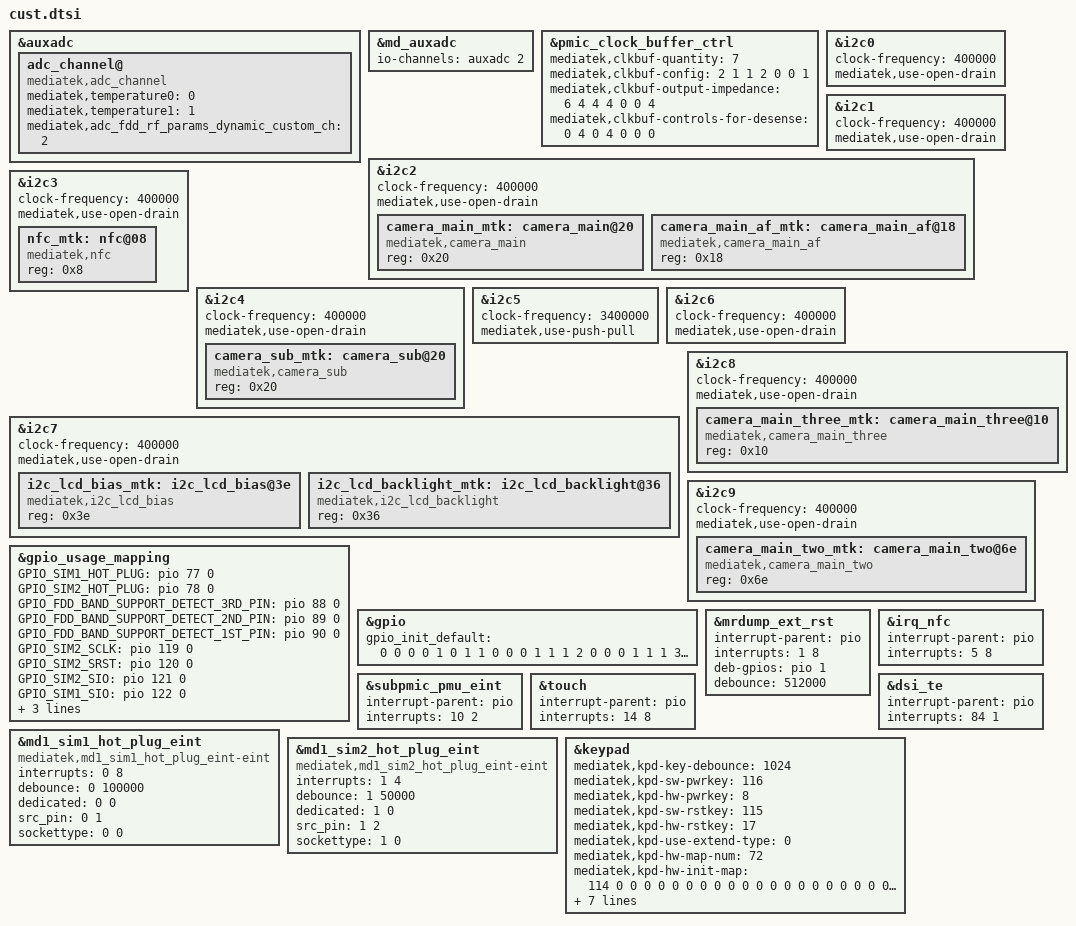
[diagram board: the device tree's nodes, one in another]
// SPDX-License-Identifier: GPL-2.0
/*
 * AQUOS wish4 (sx4) pin, EINT, I2C device, keypad and ADC configuration.
 *
 * MediaTek's DCT tool generates this file from the board's codegen.dws, which is
 * not part of the Sharp kernel release. Reconstructed from the stock dtbo; the
 * resulting dtbo.img matches the stock one byte for byte.
 */

&auxadc {
	adc_channel@ {
		compatible = "mediatek,adc_channel";
		mediatek,temperature0 = <0>;
		mediatek,temperature1 = <1>;
		mediatek,adc_fdd_rf_params_dynamic_custom_ch = <2>;
		status = "okay";
	};
};

&md_auxadc {
	io-channels = <&auxadc 2>;
};

&pmic_clock_buffer_ctrl {
	mediatek,clkbuf-quantity = <7>;
	mediatek,clkbuf-config = <2 1 1 2 0 0 1>;
	mediatek,clkbuf-output-impedance = <6 4 4 4 0 0 4>;
	mediatek,clkbuf-controls-for-desense = <0 4 0 4 0 0 0>;
	status = "okay";
};

&i2c0 {
	#address-cells = <1>;
	#size-cells = <0>;
	clock-frequency = <400000>;
	mediatek,use-open-drain;
};

&i2c1 {
	#address-cells = <1>;
	#size-cells = <0>;
	clock-frequency = <400000>;
	mediatek,use-open-drain;
};

&i2c2 {
	#address-cells = <1>;
	#size-cells = <0>;
	clock-frequency = <400000>;
	mediatek,use-open-drain;

	camera_main_mtk: camera_main@20 {
		compatible = "mediatek,camera_main";
		reg = <0x20>;
		status = "okay";
	};

	camera_main_af_mtk: camera_main_af@18 {
		compatible = "mediatek,camera_main_af";
		reg = <0x18>;
		status = "okay";
	};
};

&i2c3 {
	#address-cells = <1>;
	#size-cells = <0>;
	clock-frequency = <400000>;
	mediatek,use-open-drain;

	nfc_mtk: nfc@08 {
		compatible = "mediatek,nfc";
		reg = <0x8>;
		status = "okay";
	};
};

&i2c4 {
	#address-cells = <1>;
	#size-cells = <0>;
	clock-frequency = <400000>;
	mediatek,use-open-drain;

	camera_sub_mtk: camera_sub@20 {
		compatible = "mediatek,camera_sub";
		reg = <0x20>;
		status = "okay";
	};
};

&i2c5 {
	#address-cells = <1>;
	#size-cells = <0>;
	clock-frequency = <3400000>;
	mediatek,use-push-pull;
};

&i2c6 {
	#address-cells = <1>;
	#size-cells = <0>;
	clock-frequency = <400000>;
	mediatek,use-open-drain;
};

&i2c7 {
	#address-cells = <1>;
	#size-cells = <0>;
	clock-frequency = <400000>;
	mediatek,use-open-drain;

	i2c_lcd_bias_mtk: i2c_lcd_bias@3e {
		compatible = "mediatek,i2c_lcd_bias";
		reg = <0x3e>;
		status = "okay";
	};

	i2c_lcd_backlight_mtk: i2c_lcd_backlight@36 {
		compatible = "mediatek,i2c_lcd_backlight";
		reg = <0x36>;
		status = "okay";
	};
};

&i2c8 {
	#address-cells = <1>;
	#size-cells = <0>;
	clock-frequency = <400000>;
	mediatek,use-open-drain;

	camera_main_three_mtk: camera_main_three@10 {
		compatible = "mediatek,camera_main_three";
		reg = <0x10>;
		status = "okay";
	};
};

&i2c9 {
	#address-cells = <1>;
	#size-cells = <0>;
	clock-frequency = <400000>;
	mediatek,use-open-drain;

	camera_main_two_mtk: camera_main_two@6e {
		compatible = "mediatek,camera_main_two";
		reg = <0x6e>;
		status = "okay";
	};
};

&gpio_usage_mapping {
	GPIO_SIM1_HOT_PLUG = <&pio 77 0>;
	GPIO_SIM2_HOT_PLUG = <&pio 78 0>;
	GPIO_FDD_BAND_SUPPORT_DETECT_3RD_PIN = <&pio 88 0>;
	GPIO_FDD_BAND_SUPPORT_DETECT_2ND_PIN = <&pio 89 0>;
	GPIO_FDD_BAND_SUPPORT_DETECT_1ST_PIN = <&pio 90 0>;
	GPIO_SIM2_SCLK = <&pio 119 0>;
	GPIO_SIM2_SRST = <&pio 120 0>;
	GPIO_SIM2_SIO = <&pio 121 0>;
	GPIO_SIM1_SIO = <&pio 122 0>;
	GPIO_SIM1_SRST = <&pio 123 0>;
	GPIO_SIM1_SCLK = <&pio 124 0>;
	GPIO_RF_PWREN_RST_PIN = <&pio 170 0>;
};

&gpio {
	gpio_init_default = <0 0 0 0 1 0 1 1 0 0 0 1 1 1 2 0 0 0 1 1 1 3 0 0 0 1 0 1 4 0 0 0 1 1 1 5 0 0 0 1 0 1 6 0 1 0 1 0 1 7 0 1 0 1 0 1 8 7 0 0 1 0 1 9 0 0 0 1 1 1 10 0 0 0 1 1 1 11 0 1 0 1 0 1 12 2 0 0 0 0 0 13 2 0 0 0 0 0 14 0 0 0 1 0 1 15 0 1 0 1 0 1 16 7 0 0 1 0 1 17 7 0 0 1 0 1 18 7 0 0 1 0 1 19 7 0 0 0 0 1 20 7 0 0 1 0 1 21 0 1 0 1 0 1 22 0 0 0 1 0 1 23 7 0 0 1 0 1 24 7 0 0 1 0 1 25 7 0 0 1 0 1 26 7 0 0 1 0 1 27 1 0 0 0 0 1 28 1 0 0 0 0 1 29 1 0 0 0 0 1 30 1 0 0 1 0 1 31 2 0 0 0 0 1 32 2 0 0 0 0 1 33 2 0 0 0 0 1 34 2 0 0 1 0 1 35 0 1 0 0 0 0 36 0 1 0 0 0 0 37 0 1 0 0 0 0 38 0 1 0 1 0 0 39 0 0 0 1 1 1 40 1 0 0 0 0 1 41 1 0 0 0 0 1 42 1 0 0 1 0 1 43 1 0 0 0 0 1 44 0 1 0 1 0 1 45 0 1 0 1 0 1 46 0 0 0 1 0 0 47 0 1 0 1 0 1 48 0 0 0 1 0 1 49 1 0 0 1 0 1 50 1 0 0 1 0 1 51 1 0 0 1 0 1 52 1 0 0 0 0 1 53 0 1 0 1 0 1 54 0 1 0 1 0 1 55 0 1 0 1 0 1 56 0 1 0 1 0 1 57 0 1 1 1 0 0 58 0 1 0 1 0 1 59 1 0 0 1 0 1 60 0 1 0 1 0 1 61 1 0 0 1 1 1 62 1 0 0 0 0 1 63 1 0 0 1 1 1 64 1 0 0 0 0 1 77 1 0 0 0 0 0 78 1 0 0 1 1 1 79 1 0 0 1 1 1 80 1 0 0 1 1 1 81 3 0 0 1 0 1 82 0 1 0 1 0 1 83 1 0 0 0 0 1 84 1 0 0 1 0 1 85 1 0 0 0 0 1 86 1 0 0 0 0 1 87 2 0 0 1 0 1 88 0 0 0 0 0 0 89 0 0 0 0 0 0 90 0 0 0 0 0 0 91 0 0 0 0 0 1 92 0 1 0 1 0 1 93 0 1 0 1 0 1 94 0 1 0 1 0 1 95 1 0 0 1 0 1 96 1 0 0 1 0 1 97 2 0 0 0 0 0 98 2 0 0 0 0 0 99 2 0 0 1 1 1 100 2 0 0 1 1 1 101 1 0 0 1 1 1 102 1 0 0 1 1 1 103 1 0 0 1 1 1 104 1 0 0 1 1 1 105 1 0 0 1 1 1 106 1 0 0 1 1 1 107 1 0 0 1 1 1 108 1 0 0 1 1 1 109 1 0 0 1 1 1 110 1 0 0 1 1 1 111 1 0 0 1 1 1 112 1 0 0 1 1 1 113 1 0 0 1 1 1 114 1 0 0 1 1 1 115 1 0 0 1 0 1 116 1 0 0 1 0 1 117 0 0 0 1 0 1 118 0 0 0 1 0 1 119 1 0 0 0 0 1 120 1 0 0 0 0 1 121 1 0 0 1 1 1 122 1 0 0 1 1 1 123 1 0 0 0 0 1 124 1 0 0 0 0 1 125 1 0 0 0 0 1 126 1 0 0 1 1 1 127 1 0 0 1 1 1 128 1 0 0 1 1 1 129 1 0 0 1 1 1 130 1 0 0 1 1 1 131 0 1 0 1 0 1 132 0 1 0 1 0 1 133 0 1 0 1 0 1 134 0 1 0 1 0 1 135 0 1 0 1 0 1 136 0 1 0 1 0 1 137 0 1 0 1 0 1 138 0 1 0 1 0 1 139 0 1 0 1 0 1 140 0 1 0 1 0 1 141 1 0 0 1 1 1 142 1 0 0 1 1 1 143 1 0 0 0 0 1 144 1 0 0 0 0 1 145 1 0 0 0 0 1 146 1 0 0 0 0 1 147 1 0 0 0 0 1 148 1 0 0 0 0 1 149 1 0 0 1 0 1 150 1 0 0 1 0 1 151 1 0 0 1 0 1 152 1 0 0 1 0 1 153 1 0 0 0 0 1 154 1 0 0 0 0 1 155 1 0 0 0 0 1 156 0 0 0 1 0 1 157 1 0 0 0 0 1 158 1 0 0 0 0 1 159 1 0 0 1 0 1 160 1 0 0 1 0 1 161 1 0 0 1 0 1 162 1 0 0 0 0 0 163 1 0 0 1 0 0 164 1 0 0 1 0 1 165 1 0 0 1 0 1 166 1 0 0 0 0 1 167 1 0 0 0 0 1 168 1 0 0 0 0 1 169 1 0 0 0 0 1 170 0 1 1 1 0 1 171 1 0 0 0 0 1 172 1 0 0 0 0 1 173 1 0 0 0 0 1 174 1 0 0 0 0 1 175 0 0 0 0 0 1 176 1 0 0 0 0 1 177 0 1 0 1 0 1 178 0 1 0 1 0 1 179 0 1 0 1 0 1 180 1 0 0 0 0 1 181 1 0 0 0 0 1 182 0 0 0 0 0 0 183 0 0 0 0 0 0 184 0 0 0 0 0 0 185 0 0 0 0 0 0 186 0 0 0 0 0 0 187 0 0 0 0 0 0 188 1 0 0 0 0 0 189 1 0 0 1 0 0 190 1 0 0 0 0 0 191 1 0 0 1 0 0 192 0 0 0 1 0 1 193 0 0 0 1 0 1 194 0 0 0 1 0 1 195 0 0 0 1 0 1 196 0 0 0 1 0 1 197 0 0 0 1 0 1 198 0 0 0 1 0 1 199 0 0 0 1 0 1 200 0 0 0 1 0 1>;
};

&mrdump_ext_rst {
	interrupt-parent = <&pio>;
	interrupts = <1 8>;
	deb-gpios = <&pio 1 0>;
	debounce = <512000>;
	status = "okay";
};

&irq_nfc {
	interrupt-parent = <&pio>;
	interrupts = <5 8>;
	status = "okay";
};

&subpmic_pmu_eint {
	interrupt-parent = <&pio>;
	interrupts = <10 2>;
	status = "okay";
};

&touch {
	interrupt-parent = <&pio>;
	interrupts = <14 8>;
	status = "okay";
};

&dsi_te {
	interrupt-parent = <&pio>;
	interrupts = <84 1>;
	status = "okay";
};

&md1_sim1_hot_plug_eint {
	compatible = "mediatek,md1_sim1_hot_plug_eint-eint";
	interrupts = <0 8>;
	debounce = <0 100000>;
	dedicated = <0 0>;
	src_pin = <0 1>;
	sockettype = <0 0>;
	status = "okay";
};

&md1_sim2_hot_plug_eint {
	compatible = "mediatek,md1_sim2_hot_plug_eint-eint";
	interrupts = <1 4>;
	debounce = <1 50000>;
	dedicated = <1 0>;
	src_pin = <1 2>;
	sockettype = <1 0>;
	status = "okay";
};

&keypad {
	mediatek,kpd-key-debounce = <1024>;
	mediatek,kpd-sw-pwrkey = <116>;
	mediatek,kpd-hw-pwrkey = <8>;
	mediatek,kpd-sw-rstkey = <115>;
	mediatek,kpd-hw-rstkey = <17>;
	mediatek,kpd-use-extend-type = <0>;
	mediatek,kpd-hw-map-num = <72>;
	mediatek,kpd-hw-init-map = <114 0 0 0 0 0 0 0 0 0 0 0 0 0 0 0 0 0 0 0 0 0 0 0 0 0 0 0 0 0 0 0 0 0 0 0 0 0 0 0 0 0 0 0 0 0 0 0 0 0 0 0 0 0 0 0 0 0 0 0 0 0 0 0 0 0 0 0 0 0 0 0>;
	mediatek,kpd-pwrkey-eint-gpio = <0>;
	mediatek,kpd-pwkey-gpio-din = <0>;
	mediatek,kpd-hw-dl-key0 = <17>;
	mediatek,kpd-hw-dl-key1 = <0>;
	mediatek,kpd-hw-dl-key2 = <8>;
	mediatek,kpd-hw-recovery-key = <17>;
	mediatek,kpd-hw-factory-key = <0>;
	status = "okay";
};
